# CY8C5888LTI_LP097 register map
File version: 0.1
CY8C58LP
Registers are 8-bit, read-write, no defined reset value unless marked. A register's access mark holds for its fields unless they carry their own. Offsets are from the block's base; lines under a group give offsets from that group; [hi:lo] are bit positions; {n}, {i} and the like mark numbered series; 'fields as' and 'values as' point back to an identical list; <NAME> marks a mode.

## Memory map
0x00000000 IMU_UART — UART
0x00000000 HOST_UART — UART

## IMU_UART — UART
Base 0x00000000
0x40006425 RX_IMU_UART_RX_ADDRESS1 — RX Address1 Register
0x40006435 RX_IMU_UART_RX_ADDRESS2 — RX Address2 Register
0x40006445 RX_IMU_UART_RX_DATA — RX Data Register
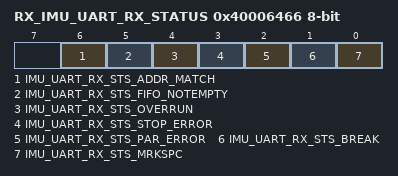
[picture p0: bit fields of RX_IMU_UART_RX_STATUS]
0x40006466 RX_IMU_UART_RX_STATUS — RX status register
  [6] IMU_UART_RX_STS_ADDR_MATCH ro, [5] IMU_UART_RX_STS_FIFO_NOTEMPTY ro, [4] IMU_UART_RX_STS_OVERRUN ro, [3] IMU_UART_RX_STS_STOP_ERROR ro, [2] IMU_UART_RX_STS_PAR_ERROR ro, [1] IMU_UART_RX_STS_BREAK ro, [0] IMU_UART_RX_STS_MRKSPC ro

## HOST_UART — UART
Base 0x00000000
0x40006424 RX_HOST_UART_RX_ADDRESS1 — RX Address1 Register
0x40006434 RX_HOST_UART_RX_ADDRESS2 — RX Address2 Register
0x40006444 RX_HOST_UART_RX_DATA — RX Data Register
0x40006447 TX_HOST_UART_TX_DATA — TX Data Register
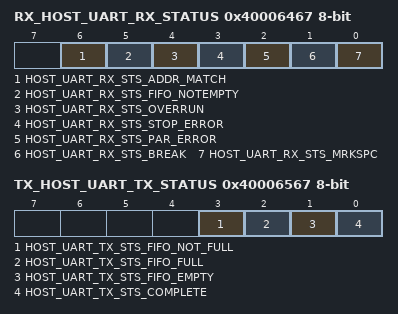
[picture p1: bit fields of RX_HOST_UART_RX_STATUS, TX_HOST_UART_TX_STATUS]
0x40006467 RX_HOST_UART_RX_STATUS — RX status register
  [6] HOST_UART_RX_STS_ADDR_MATCH ro, [5] HOST_UART_RX_STS_FIFO_NOTEMPTY ro, [4] HOST_UART_RX_STS_OVERRUN ro, [3] HOST_UART_RX_STS_STOP_ERROR ro, [2] HOST_UART_RX_STS_PAR_ERROR ro, [1] HOST_UART_RX_STS_BREAK ro, [0] HOST_UART_RX_STS_MRKSPC ro
0x40006567 TX_HOST_UART_TX_STATUS — TX status register
  [3] HOST_UART_TX_STS_FIFO_NOT_FULL ro, [2] HOST_UART_TX_STS_FIFO_FULL ro, [1] HOST_UART_TX_STS_FIFO_EMPTY ro, [0] HOST_UART_TX_STS_COMPLETE ro
